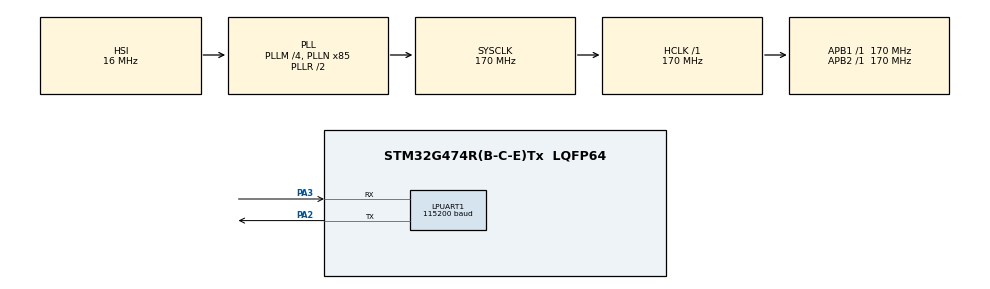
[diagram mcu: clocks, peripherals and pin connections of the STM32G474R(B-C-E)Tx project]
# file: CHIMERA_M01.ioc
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LPUART1.BaudRate=115200
Mcu.Family=STM32G4
Mcu.Name=STM32G474R(B-C-E)Tx
Mcu.Package=LQFP64
NUCLEO-G474RE.BUTTON=1
NUCLEO-G474RE.LD2=true
NUCLEO-G474RE.VCP=false
NVIC.EXTI15_10_IRQn=true\:0\:0\:false\:false\:true\:false\:true\:true
NVIC.LPUART1_IRQn=true\:0\:0\:false\:false\:true\:true\:true\:true
NVIC.PriorityGroup=NVIC_PRIORITYGROUP_4
PA13.GPIO_Label=T_SWDIO
PA13.Signal=SYS_JTMS-SWDIO
PA14.GPIO_Label=T_SWCLK
PA14.Signal=SYS_JTCK-SWCLK
PA2.Mode=Asynchronous
PA2.Signal=LPUART1_TX
PA3.Mode=Asynchronous
PA3.Signal=LPUART1_RX
PB3.GPIO_Label=T_SWO
PB3.Signal=SYS_JTDO-SWO
PC14-OSC32_IN.GPIO_Label=RCC_OSC32_IN
PC14-OSC32_IN.Signal=RCC_OSC32_IN
PC15-OSC32_OUT.GPIO_Label=RCC_OSC32_OUT
PC15-OSC32_OUT.Signal=RCC_OSC32_OUT
PF0-OSC_IN.GPIO_Label=RCC_OSC_IN
PF0-OSC_IN.Signal=RCC_OSC_IN
PF1-OSC_OUT.GPIO_Label=RCC_OSC_OUT
PF1-OSC_OUT.Signal=RCC_OSC_OUT
ProjectManager.HeapSize=0x200
ProjectManager.StackSize=0x400
ProjectManager.TargetToolchain=CMake
RCC.ADC12Freq_Value=170000000
RCC.ADC345Freq_Value=170000000
RCC.AHBFreq_Value=170000000
RCC.APB1Freq_Value=170000000
RCC.APB1TimFreq_Value=170000000
RCC.APB2Freq_Value=170000000
RCC.APB2TimFreq_Value=170000000
RCC.CortexFreq_Value=170000000
RCC.EXTERNAL_CLOCK_VALUE=12288000
RCC.HCLKFreq_Value=170000000
RCC.HSE_VALUE=24000000
RCC.HSI48_VALUE=48000000
RCC.HSI_VALUE=16000000
RCC.LSE_VALUE=32768
RCC.PLLM=RCC_PLLM_DIV4
RCC.PLLN=85
RCC.RTCClockSelection=RCC_RTCCLKSOURCE_LSE
RCC.SYSCLKFreq_VALUE=170000000
RCC.SYSCLKSource=RCC_SYSCLKSOURCE_PLLCLK
RCC.USBFreq_Value=170000000
RCC.VCOOutputFreq_Value=340000000
VP_NUCLEO-G474RE_VS_BSP_COMMON.Mode=COMMON
VP_SYS_VS_DBSignals.Mode=DisableDeadBatterySignals
board=NUCLEO-G474RE

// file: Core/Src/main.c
/* USER CODE BEGIN Header */
/**
  ******************************************************************************
  * @file           : main.c
  * @brief          : Main program body
  ******************************************************************************
  * @attention
  *
  * Copyright (c) 2026 STMicroelectronics.
  * All rights reserved.
  *
  * This software is licensed under terms that can be found in the LICENSE file
  * in the root directory of this software component.
  * If no LICENSE file comes with this software, it is provided AS-IS.
  *
  ******************************************************************************
  */
/* USER CODE END Header */
#include "main.h"

/* USER CODE BEGIN Includes */
#include <string.h>
// #include "chimera_commands.h"
#include "chimera_input.h"
#include "chimera_runtime.h"
// #include "chimera_status.h"
#include "stm32g4xx_nucleo.h"

/* USER CODE END Includes */

UART_HandleTypeDef hlpuart1;

void SystemClock_Config(void);
static void MX_GPIO_Init(void);
static void MX_LPUART1_UART_Init(void);
/* USER CODE BEGIN PFP */
HAL_StatusTypeDef SendResponse(const char *message);
// void ProcessCommand(const char *command, uint32_t uptime_ms);
/* USER CODE END PFP */

int main(void)
{

  /* MCU Configuration--------------------------------------------------------*/

  /* Reset of all peripherals, Initializes the Flash interface and the Systick. */
  HAL_Init();

  /* Configure the system clock */
  SystemClock_Config();

  /* Initialize all configured peripherals */
  MX_GPIO_Init();
  MX_LPUART1_UART_Init();
  /* USER CODE BEGIN 2 */
  /* Initialize led */
  BSP_LED_Init(LED_GREEN);

  /* Initialize USER push-button, will be used to trigger an interrupt each time it's pressed.*/
  BSP_PB_Init(BUTTON_USER, BUTTON_MODE_EXTI);

  // Create the message we want to send over UART
  uint8_t message[] = "CHIMERA M01 Boot\r\n";
  uint8_t incoming = 0;
  // uint8_t command[16];
  // uint8_t index = 0;
  // uint8_t command_overflow = 0;
  ChimeraInput input;
  ChimeraInput_Init(&input);

  // Transmit the message and capture the result
  HAL_StatusTypeDef result = HAL_UART_Transmit(
    &hlpuart1,
    message,
    sizeof(message) - 1,
    1000
  );

  // Check whether the transmission failed
  if (result != HAL_OK)
  {
    Error_Handler();
  }

  /* USER CODE END 2 */

  /* Initialize led */
  BSP_LED_Init(LED_GREEN);

  /* Initialize USER push-button, will be used to trigger an interrupt each time it's pressed.*/
  BSP_PB_Init(BUTTON_USER, BUTTON_MODE_EXTI);

  /* Infinite loop */
  while (1)
  {

    /* USER CODE BEGIN 3 */
    // BSP_LED_Toggle(LED_GREEN);
    // HAL_Delay(500);

    // Wait for a single byte to be received over UART
    // HAL_StatusTypeDef result = HAL_UART_Receive(
    //   &hlpuart1,
    //   &incoming,
    //   1,
    //   HAL_MAX_DELAY
    // );
    if (HAL_UART_Receive(&hlpuart1, &incoming, 1, HAL_MAX_DELAY) != HAL_OK)
    {
      Error_Handler();
    }

    // Check whether we received "PING"
    ChimeraInputResult input_result = ChimeraInput_Feed(
      &input,
      (char)incoming
    );

    if (input_result == CHIMERA_INPUT_READY)
    {
      char response[128];

      int written = ProcessCommand(
        input.command,
        HAL_GetTick(),
        response,
        sizeof(response)
      );

      if (written < 0 || (size_t)written >= sizeof(response))
      {
        Error_Handler();
      }

      if (SendResponse(response) != HAL_OK)
      {
        Error_Handler();
      }
    }
    else if (input_result == CHIMERA_INPUT_OVERFLOW)
    {
      if (SendResponse("ERROR: COMMAND TOO LONG\r\n") != HAL_OK)
      {
        Error_Handler();
      }
    }
    // if (result == HAL_OK)
    // {
    //   if (incoming == '\r' || incoming == '\n')
    //   {
    //     command[index] = '\0';

    //     if (command_overflow == 1)
    //     {
    //       if (SendResponse("ERROR: COMMAND TOO LONG\r\n") != HAL_OK)
    //       {
    //         Error_Handler();
    //       }
    //     }
    //     else if (index > 0)
    //     {
    //       // ProcessCommand((const char *)command, HAL_GetTick());
    //       char response[128];

    //       int written = ProcessCommand(
    //         (const char *)command,
    //         HAL_GetTick(),
    //         response,
    //         sizeof(response)
    //       );

    //       if (written < 0 || (size_t)written >= sizeof(response))
    //       {
    //         Error_Handler();
    //       }

    //       if (SendResponse(response) != HAL_OK)
    //       {
    //         Error_Handler();
    //       }
    //     }

    //     index = 0;
    //     command_overflow = 0;
    //   }
    //   else if (index < sizeof(command) - 1)
    //   {
    //     command[index] = incoming;
    //     index++;
    //   }
    //   else
    //   {
    //     // Command exceeded buffer size
    //     command_overflow = 1;
    //   }
    // }
  }
  /* USER CODE END 3 */
}

void SystemClock_Config(void)
{
  RCC_OscInitTypeDef RCC_OscInitStruct = {0};
  RCC_ClkInitTypeDef RCC_ClkInitStruct = {0};

  /** Configure the main internal regulator output voltage
  */
  HAL_PWREx_ControlVoltageScaling(PWR_REGULATOR_VOLTAGE_SCALE1_BOOST);

  /** Initializes the RCC Oscillators according to the specified parameters
  * in the RCC_OscInitTypeDef structure.
  */
  RCC_OscInitStruct.OscillatorType = RCC_OSCILLATORTYPE_HSI;
  RCC_OscInitStruct.HSIState = RCC_HSI_ON;
  RCC_OscInitStruct.HSICalibrationValue = RCC_HSICALIBRATION_DEFAULT;
  RCC_OscInitStruct.PLL.PLLState = RCC_PLL_ON;
  RCC_OscInitStruct.PLL.PLLSource = RCC_PLLSOURCE_HSI;
  RCC_OscInitStruct.PLL.PLLM = RCC_PLLM_DIV4;
  RCC_OscInitStruct.PLL.PLLN = 85;
  RCC_OscInitStruct.PLL.PLLP = RCC_PLLP_DIV2;
  RCC_OscInitStruct.PLL.PLLQ = RCC_PLLQ_DIV2;
  RCC_OscInitStruct.PLL.PLLR = RCC_PLLR_DIV2;
  if (HAL_RCC_OscConfig(&RCC_OscInitStruct) != HAL_OK)
  {
    Error_Handler();
  }

  /** Initializes the CPU, AHB and APB buses clocks
  */
  RCC_ClkInitStruct.ClockType = RCC_CLOCKTYPE_HCLK|RCC_CLOCKTYPE_SYSCLK
                              |RCC_CLOCKTYPE_PCLK1|RCC_CLOCKTYPE_PCLK2;
  RCC_ClkInitStruct.SYSCLKSource = RCC_SYSCLKSOURCE_PLLCLK;
  RCC_ClkInitStruct.AHBCLKDivider = RCC_SYSCLK_DIV1;
  RCC_ClkInitStruct.APB1CLKDivider = RCC_HCLK_DIV1;
  RCC_ClkInitStruct.APB2CLKDivider = RCC_HCLK_DIV1;

  if (HAL_RCC_ClockConfig(&RCC_ClkInitStruct, FLASH_LATENCY_4) != HAL_OK)
  {
    Error_Handler();
  }
}

static void MX_LPUART1_UART_Init(void)
{

  hlpuart1.Instance = LPUART1;
  hlpuart1.Init.BaudRate = 115200;
  hlpuart1.Init.WordLength = UART_WORDLENGTH_8B;
  hlpuart1.Init.StopBits = UART_STOPBITS_1;
  hlpuart1.Init.Parity = UART_PARITY_NONE;
  hlpuart1.Init.Mode = UART_MODE_TX_RX;
  hlpuart1.Init.HwFlowCtl = UART_HWCONTROL_NONE;
  hlpuart1.Init.OneBitSampling = UART_ONE_BIT_SAMPLE_DISABLE;
  hlpuart1.Init.ClockPrescaler = UART_PRESCALER_DIV1;
  hlpuart1.AdvancedInit.AdvFeatureInit = UART_ADVFEATURE_NO_INIT;
  if (HAL_UART_Init(&hlpuart1) != HAL_OK)
  {
    Error_Handler();
  }
  if (HAL_UARTEx_SetTxFifoThreshold(&hlpuart1, UART_TXFIFO_THRESHOLD_1_8) != HAL_OK)
  {
    Error_Handler();
  }
  if (HAL_UARTEx_SetRxFifoThreshold(&hlpuart1, UART_RXFIFO_THRESHOLD_1_8) != HAL_OK)
  {
    Error_Handler();
  }
  if (HAL_UARTEx_DisableFifoMode(&hlpuart1) != HAL_OK)
  {
    Error_Handler();
  }

}

static void MX_GPIO_Init(void)
{

  /* GPIO Ports Clock Enable */
  __HAL_RCC_GPIOC_CLK_ENABLE();
  __HAL_RCC_GPIOF_CLK_ENABLE();
  __HAL_RCC_GPIOA_CLK_ENABLE();
  __HAL_RCC_GPIOB_CLK_ENABLE();

}

/* USER CODE BEGIN 4 */
HAL_StatusTypeDef SendResponse(const char *message)
{
  return HAL_UART_Transmit(
    &hlpuart1,
    (const uint8_t *)message,
    strlen(message),
    1000
  );
}

// void ProcessCommand(const char *command, uint32_t uptime_ms)
// {
//   ChimeraCommand parsed = ChimeraCommands_Parse(command);
//   HAL_StatusTypeDef result;

//   switch (parsed)
//   {
//     case CHIMERA_CMD_PING:
//       result = SendResponse("PONG\r\n");
//       break;

//     case CHIMERA_CMD_HELP:
//       result = SendResponse("COMMANDS: PING, HELP, STATUS\r\n");
//       break;

//     case CHIMERA_CMD_STATUS:
//     {
//       char response[128];

//       int written = FormatStatus(
//         uptime_ms,
//         response,
//         sizeof(response)
//       );

//       if (written < 0 || (size_t)written >= sizeof(response))
//       {
//         Error_Handler();
//       }

//       // FormatStatus(uptime_ms, response, sizeof(response));

//       result = SendResponse(response);
//       break;
//     }

//     default:
//       result = SendResponse("UNKNOWN COMMAND\r\n");
//       break;
//   }

//   if (result != HAL_OK)
//   {
//     Error_Handler();
//   }
// }

/* USER CODE END 4 */

void Error_Handler(void)
{
  __disable_irq();
  while (1)
  {
  }
}
